AUTOSAR XML (schema 4-2-2)
package /Components
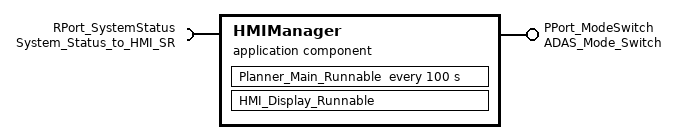
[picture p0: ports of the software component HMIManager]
  application sw component type HMIManager
    provide port PPort_ModeSwitch: provided-interface=ADAS_Mode_Switch
    require port RPort_SystemStatus: required-interface=System_Status_to_HMI_SR
    behavior HMIManager_Behavior
      external trigger occurred event Driver_Input: start-on-event=Camera_Inference_Runnable
      operation invoked event Mode_Switch_Invoked: start-on-event=Planner_Main_Runnable
      timing event HMI_Update: start-on-event=Planner_Main_Runnable, period=100
      runnable HMI_Display_Runnable: minimum-start-interval=100, symbol=HMIManager_HMI_Display_Runnable
        data-receive-point-by-values:
          access ADAS_Status_Access: accessed-variable=RPort_SystemStatus.ADAS_Status
        data-send-points:
          access ModeSwitch_Send: accessed-variable=PPort_ModeSwitch.RequestedMode
